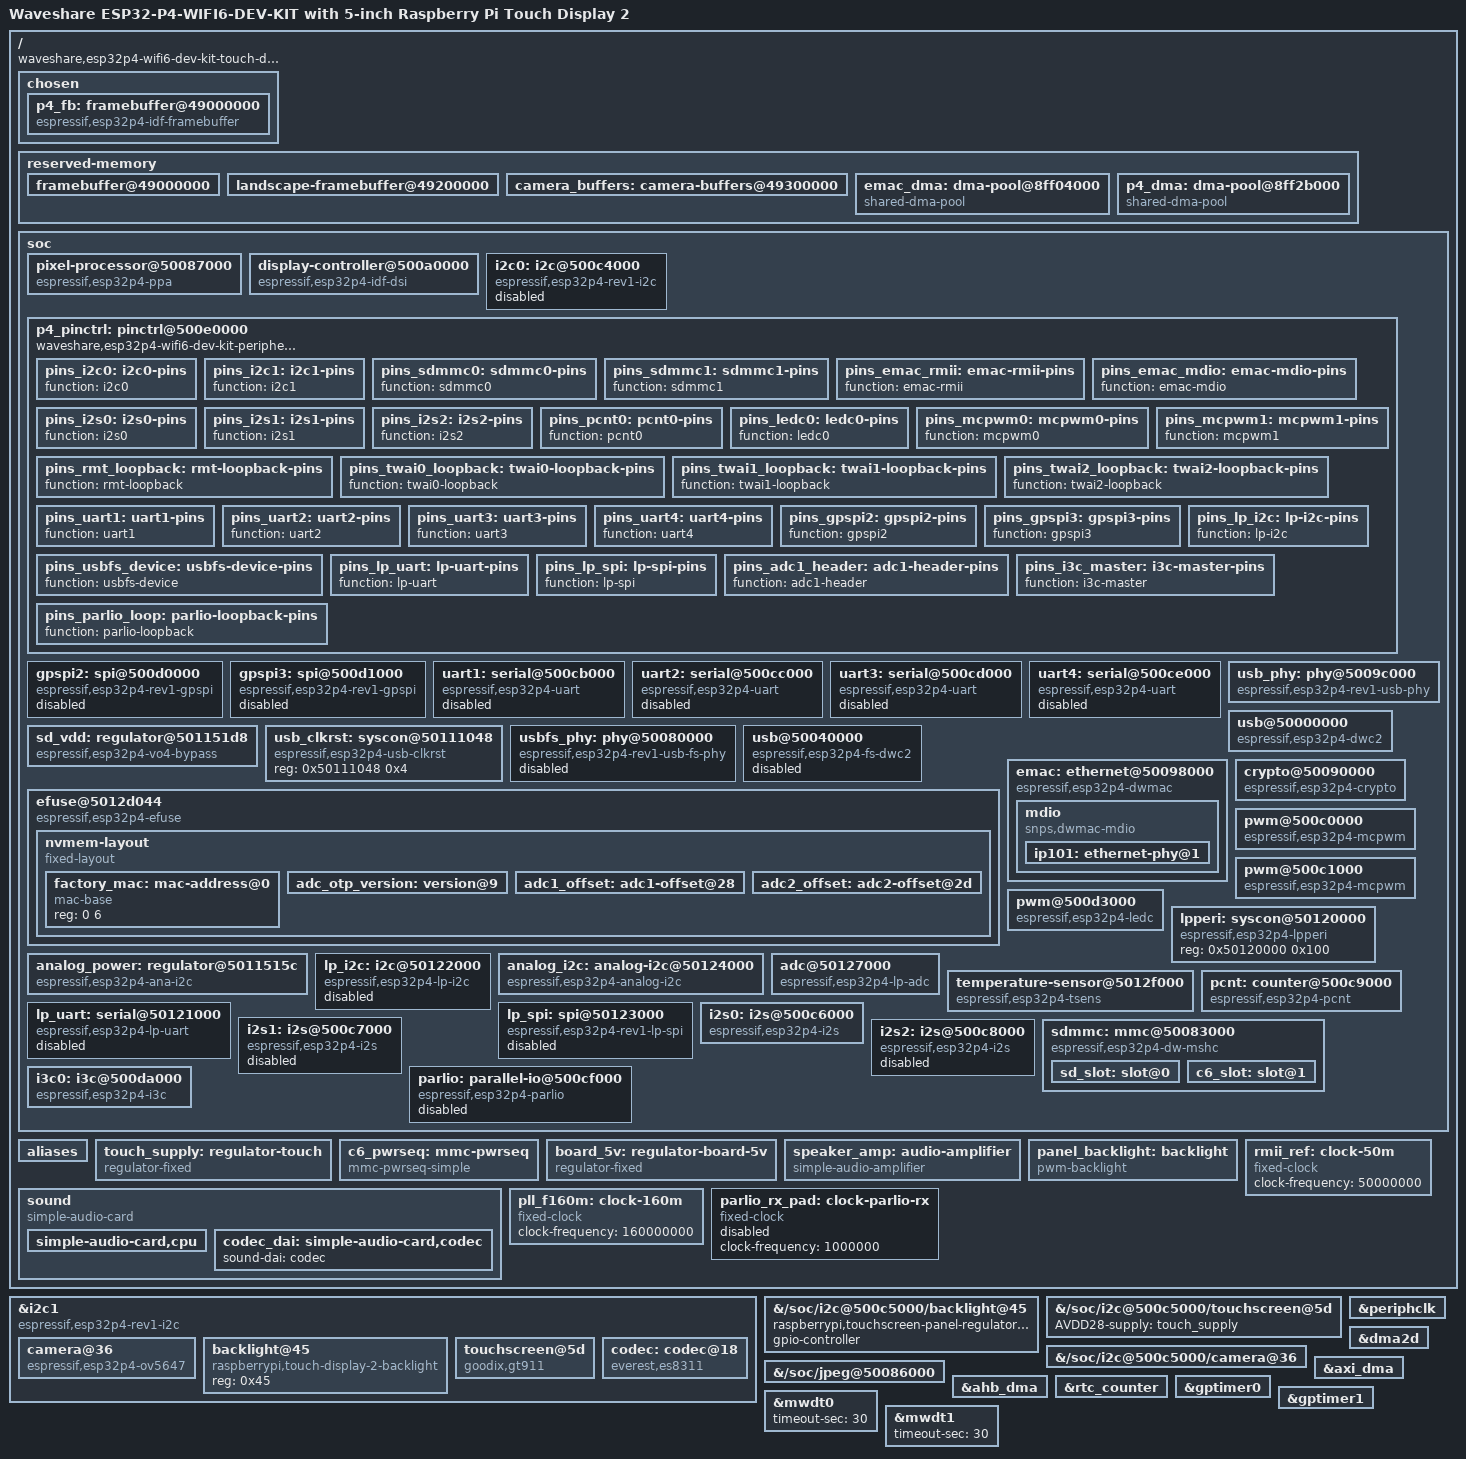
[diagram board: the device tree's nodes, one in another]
// SPDX-License-Identifier: (GPL-2.0-only OR BSD-2-Clause)
#include <dt-bindings/gpio/gpio.h>
#include <dt-bindings/clock/esp32p4-peripheral-clock.h>
#include <dt-bindings/interrupt-controller/irq.h>

/dts-v1/;
#include "esp32p4-generic.dtsi"

/ {
	chosen {
		p4_fb: framebuffer@49000000 {
			interrupts = <0x18 0x04>;
			interrupt-parent = <0x01>;
			espressif,ppa-service-entry = <0x00>;
			espressif,logical-framebuffer = <0x49200000 0xe1000 640 360 1280 720>;
			espressif,rotation-controller = <0x04>;
			espressif,scanout-controller = <0x03>;
			espressif,panel-i2c = <&i2c1>;
			espressif,panel-i2c-address = <0x45>;
			status = "okay";
			format = "r5g6b5";
			stride = <0x5a0>;
			height = <0x500>;
			width = <0x2d0>;
			reg = <0x49000000 0x1c2000>;
			compatible = "espressif,esp32p4-idf-framebuffer";
		};
	};

	reserved-memory {
		framebuffer@49000000 {
			no-map;
			reg = <0x49000000 0x1c2000>;
		};

		landscape-framebuffer@49200000 {
			no-map;
			reg = <0x49200000 0xe1000>;
		};

		camera_buffers: camera-buffers@49300000 {
			no-map;
			reg = <0x49300000 0x300000>;
		};
	};

	soc {
		pixel-processor@50087000 {
			compatible = "espressif,esp32p4-idf-ppa";
			reg = <0x50087000 0x1000 0x50088000 0x1000>;
			interrupt-parent = <0x01>;
			interrupts = <105 4 108 4>;
			phandle = <0x04>;
		};

		display-controller@500a0000 {
			compatible = "espressif,esp32p4-idf-dsi";
			reg = <0x500a0000 0x1000 0x500e603c 0x04>;
			interrupt-parent = <0x01>;
			interrupts = <86 4>;
			phandle = <0x03>;
		};
	};
};

/* Set to 1 to select UART4 DMA and reserve AHB GDMA pair 2 for it. */
#define ESP32P4_UART4_UHCI 0

&{/soc} {

	/* TRM ch.48 I2C Controller — HP I2C0 master and IRQ44. */
	i2c0: i2c@500c4000 {
		compatible = "espressif,esp32p4-rev1-i2c";
		reg = <0x500c4000 0x100>;
		interrupt-parent = <&{/soc/interrupt-controller@20800000}>;
		interrupts = <44 4>;
		clocks = <&periphclk ESP32P4_CLK_I2C0>;
		resets = <&periphclk ESP32P4_RST_I2C0>;
		pinctrl-names = "default";
		pinctrl-0 = <&pins_i2c0>;
		clock-frequency = <100000>;
		#address-cells = <1>;
		#size-cells = <0>;
		/* I2C1 owns the display pads by default. */
		status = "disabled";
	};

	p4_pinctrl: pinctrl@500e0000 {
		compatible = "waveshare,esp32p4-wifi6-dev-kit-peripheral-pinctrl";
		reg = <0x500e0000 0x700>, <0x500e1000 0x100>;
		clocks = <&periphclk ESP32P4_CLK_IOMUX>;

		pins_i2c0: i2c0-pins {
			function = "i2c0";
		};

		pins_i2c1: i2c1-pins {
			function = "i2c1";
		};

		pins_sdmmc0: sdmmc0-pins {
			function = "sdmmc0";
		};

		pins_sdmmc1: sdmmc1-pins {
			function = "sdmmc1";
		};

		pins_emac_rmii: emac-rmii-pins {
			function = "emac-rmii";
		};

		pins_emac_mdio: emac-mdio-pins {
			function = "emac-mdio";
		};

		pins_i2s0: i2s0-pins {
			function = "i2s0";
		};

		pins_i2s1: i2s1-pins {
			function = "i2s1";
		};

		pins_i2s2: i2s2-pins {
			function = "i2s2";
		};

		pins_pcnt0: pcnt0-pins {
			function = "pcnt0";
		};

		pins_ledc0: ledc0-pins {
			function = "ledc0";
		};

		pins_mcpwm0: mcpwm0-pins {
			function = "mcpwm0";
		};

		pins_mcpwm1: mcpwm1-pins {
			function = "mcpwm1";
		};

		pins_rmt_loopback: rmt-loopback-pins {
			function = "rmt-loopback";
		};

		pins_twai0_loopback: twai0-loopback-pins {
			function = "twai0-loopback";
		};

		pins_twai1_loopback: twai1-loopback-pins {
			function = "twai1-loopback";
		};

		pins_twai2_loopback: twai2-loopback-pins {
			function = "twai2-loopback";
		};

		pins_uart1: uart1-pins {
			function = "uart1";
		};

		pins_uart2: uart2-pins {
			function = "uart2";
		};

		pins_uart3: uart3-pins {
			function = "uart3";
		};

		pins_uart4: uart4-pins {
			function = "uart4";
		};

		pins_gpspi2: gpspi2-pins {
			function = "gpspi2";
		};

		pins_gpspi3: gpspi3-pins {
			function = "gpspi3";
		};
	};
};

/ {
	aliases {
		spi2 = &gpspi2;
		spi3 = &gpspi3;
	};
};

&{/soc} {
	/* TRM ch.47 SPI Controller and ch.14 Interrupt Matrix — SPI2/3. */
	/* P6 GPIO20..23. No implicit spidev or external device. */
	gpspi2: spi@500d0000 {
		compatible = "espressif,esp32p4-rev1-gpspi";
		reg = <0x500d0000 0x100>;
		clocks = <&periphclk ESP32P4_CLK_GPSPI2>;
		resets = <&periphclk ESP32P4_RST_GPSPI2>;
		interrupt-parent = <&{/soc/interrupt-controller@20800000}>;
		interrupts = <25 IRQ_TYPE_LEVEL_HIGH>;
		pinctrl-0 = <&pins_gpspi2>;
		pinctrl-names = "default";
		num-cs = <1>;
		#address-cells = <1>;
		#size-cells = <0>;
		status = "disabled";
	};

	/* P6 GPIO20..23. No implicit spidev or external device. */
	gpspi3: spi@500d1000 {
		compatible = "espressif,esp32p4-rev1-gpspi";
		reg = <0x500d1000 0x100>;
		clocks = <&periphclk ESP32P4_CLK_GPSPI3>;
		resets = <&periphclk ESP32P4_RST_GPSPI3>;
		interrupt-parent = <&{/soc/interrupt-controller@20800000}>;
		interrupts = <26 IRQ_TYPE_LEVEL_HIGH>;
		pinctrl-0 = <&pins_gpspi3>;
		pinctrl-names = "default";
		num-cs = <1>;
		#address-cells = <1>;
		#size-cells = <0>;
		status = "disabled";
	};
};

/ {
	aliases {
		serial1 = &uart1;
		serial2 = &uart2;
		serial3 = &uart3;
		serial4 = &uart4;
	};
};

&{/soc} {
	/* TRM ch.46 UART Controller and ch.14 Interrupt Matrix. */
	uart1: serial@500cb000 {
		compatible = "espressif,esp32p4-uart";
		reg = <0x500cb000 0x1000>;
		interrupt-parent = <&{/soc/interrupt-controller@20800000}>;
		interrupts = <32 IRQ_TYPE_LEVEL_HIGH>;
		clocks = <&periphclk ESP32P4_CLK_UART1>;
		resets = <&periphclk ESP32P4_RST_UART1>;
		pinctrl-names = "default";
		pinctrl-0 = <&pins_uart1>;
		status = "disabled";
	};

	uart2: serial@500cc000 {
		compatible = "espressif,esp32p4-uart";
		reg = <0x500cc000 0x1000>;
		interrupt-parent = <&{/soc/interrupt-controller@20800000}>;
		interrupts = <33 IRQ_TYPE_LEVEL_HIGH>;
		clocks = <&periphclk ESP32P4_CLK_UART2>;
		resets = <&periphclk ESP32P4_RST_UART2>;
		pinctrl-names = "default";
		pinctrl-0 = <&pins_uart2>;
		status = "disabled";
	};

	uart3: serial@500cd000 {
		compatible = "espressif,esp32p4-uart";
		reg = <0x500cd000 0x1000>;
		interrupt-parent = <&{/soc/interrupt-controller@20800000}>;
		interrupts = <34 IRQ_TYPE_LEVEL_HIGH>;
		clocks = <&periphclk ESP32P4_CLK_UART3>;
		resets = <&periphclk ESP32P4_RST_UART3>;
		pinctrl-names = "default";
		pinctrl-0 = <&pins_uart3>;
		status = "disabled";
	};

	uart4: serial@500ce000 {
		compatible = "espressif,esp32p4-uart";
		reg = <0x500ce000 0x1000>;
		interrupt-parent = <&{/soc/interrupt-controller@20800000}>;
		interrupts = <35 IRQ_TYPE_LEVEL_HIGH>;
		clocks = <&periphclk ESP32P4_CLK_UART4>;
		resets = <&periphclk ESP32P4_RST_UART4>;
		pinctrl-names = "default";
		pinctrl-0 = <&pins_uart4>;
		status = "disabled";
	};
};

/ {
	model = "Waveshare ESP32-P4-WIFI6-DEV-KIT with 5-inch Raspberry Pi Touch Display 2";
	compatible = "waveshare,esp32p4-wifi6-dev-kit-touch-display-2",
		     "waveshare,esp32p4-wifi6-dev-kit",
		     "espressif,esp32p4-generic", "espressif,esp32p4";

	aliases {
		i2c1 = &i2c1;
		spi4 = &lp_spi;
		serial5 = &lp_uart;
		mmc0 = &sd_slot;
		mmc1 = &c6_slot;
		ethernet0 = &emac;
		watchdog0 = &mwdt0;
		watchdog1 = &mwdt1;
	};

	/* The panel MCU exposes LCD reset on GPIO0 and CTP reset on GPIO1. */
	touch_supply: regulator-touch {
		compatible = "regulator-fixed";
		regulator-name = "touch-display-2";
		gpio = <&panel_mcu 1 GPIO_ACTIVE_HIGH>;
		enable-active-high;
		startup-delay-us = <50000>;
	};

	c6_pwrseq: mmc-pwrseq {
		compatible = "mmc-pwrseq-simple";
		reset-gpios = <&p4_pinctrl 54 GPIO_ACTIVE_LOW>;
		/* ESP-Hosted firmware starts after the SDIO bus is pulled up. */
		post-power-on-delay-ms = <200>;
		power-off-delay-us = <10000>;
	};

	board_5v: regulator-board-5v {
		compatible = "regulator-fixed";
		regulator-name = "VCC_5V";
		regulator-min-microvolt = <5000000>;
		regulator-max-microvolt = <5000000>;
		regulator-always-on;
	};

	speaker_amp: audio-amplifier {
		compatible = "simple-audio-amplifier";
		enable-gpios = <&p4_pinctrl 53 GPIO_ACTIVE_HIGH>;
		VCC-supply = <&board_5v>;
		sound-name-prefix = "PA";
	};

	sound {
		compatible = "simple-audio-card";
		simple-audio-card,name = "Waveshare ES8311";
		simple-audio-card,format = "i2s";
		simple-audio-card,bitclock-master = <&codec_dai>;
		simple-audio-card,frame-master = <&codec_dai>;
		simple-audio-card,mclk-fs = <256>;
		simple-audio-card,aux-devs = <&speaker_amp>;
		simple-audio-card,widgets = "Speaker", "Speaker", "Microphone", "Mic";
		simple-audio-card,routing = "Speaker", "PA OUTL", "PA INL", "OUT",
					   "MIC1", "Mic";

		simple-audio-card,cpu {
			sound-dai = <&i2s0>;
			system-clock-direction-out;
		};

		codec_dai: simple-audio-card,codec {
			sound-dai = <&codec>;
		};
	};

	panel_backlight: backlight {
		compatible = "pwm-backlight";
		pwms = <&panel_mcu 0 200000 0>;
		brightness-levels = <0 31>;
		num-interpolated-steps = <31>;
		default-brightness-level = <16>;
	};
};

/* TRM ch.48 I2C Controller - I2C1 APB gate, XTAL source and master mode.
 * The panel MCU and touchscreen are on GPIO7 (SDA) and GPIO8 (SCL).
 */
&i2c1 {
	/delete-property/ status;
	compatible = "espressif,esp32p4-rev1-i2c";
	reg = <0x500c5000 0x100>;
	clocks = <&periphclk ESP32P4_CLK_I2C1>;
	resets = <&periphclk ESP32P4_RST_I2C1>;
	pinctrl-0 = <&pins_i2c1>;
	pinctrl-names = "default";
	clock-frequency = <100000>;

	camera@36 {
		compatible = "espressif,esp32p4-ov5647";
		reg = <0x36>;
		interrupt-parent = <0x01>;
		interrupts = <24 4>;
	};

	backlight@45 {
		compatible = "raspberrypi,touch-display-2-backlight";
		reg = <0x45>;
	};

	touchscreen@5d {
		compatible = "goodix,gt911";
		reg = <0x5d>;
		touchscreen-size-x = <720>;
		touchscreen-size-y = <1280>;
		touchscreen-inverted-x;
		touchscreen-swapped-x-y;
		touchscreen-x-mm = <62>;
		touchscreen-y-mm = <110>;
	};

	codec: codec@18 {
		compatible = "everest,es8311";
		reg = <0x18>;
		clocks = <&periphclk ESP32P4_CLK_I2S0>;
		clock-names = "mclk";
		#sound-dai-cells = <0>;
	};
};

&{/chosen/framebuffer@49000000} {
	reset-gpios = <&panel_mcu 0 GPIO_ACTIVE_LOW>;
	backlight = <&panel_backlight>;
};

panel_mcu: &{/soc/i2c@500c5000/backlight@45} {
	compatible = "raspberrypi,touchscreen-panel-regulator-v2";
	gpio-controller;
	#gpio-cells = <2>;
	#pwm-cells = <3>;
};

&{/soc/i2c@500c5000/touchscreen@5d} {
	AVDD28-supply = <&touch_supply>;
};

/* TRM ch.9 System and Memory - CPU and DMA aliases of HP L2MEM. */
&{/reserved-memory} {
	emac_dma: dma-pool@8ff04000 {
		compatible = "shared-dma-pool";
		reg = <0x8ff04000 0x10000>;
		no-map;
	};

	p4_dma: dma-pool@8ff2b000 {
		compatible = "shared-dma-pool";
		reg = <0x8ff2b000 0x11000>;
		no-map;
		linux,dma-default;
	};
};

&{/soc} {
	dma-noncoherent;
	dma-ranges = <0x48000000 0x48000000 0x04000000>,
		     <0x4ff04000 0x8ff04000 0x10000>,
		     <0x4ff2b000 0x8ff2b000 0x11000>;
};

/ {
	rmii_ref: clock-50m {
		compatible = "fixed-clock";
		#clock-cells = <0>;
		clock-frequency = <50000000>;
	};

	pll_f160m: clock-160m {
		compatible = "fixed-clock";
		#clock-cells = <0>;
		clock-frequency = <160000000>;
	};
};

&p4_pinctrl {
	reg = <0x500e0000 0x700>, <0x500e1000 0x100>,
	      <0x5012a000 0x200>, <0x5012b000 0x100>;
	gpio-controller;
	#gpio-cells = <2>;
	gpio-ranges = <&p4_pinctrl 0 0 57>;
	gpio-reserved-ranges = <0 51>, <52 1>, <55 2>;

	pins_lp_i2c: lp-i2c-pins {
		function = "lp-i2c";
	};

	pins_usbfs_device: usbfs-device-pins {
		function = "usbfs-device";
	};

	pins_lp_uart: lp-uart-pins {
		function = "lp-uart";
	};

	pins_lp_spi: lp-spi-pins {
		function = "lp-spi";
	};

	pins_adc1_header: adc1-header-pins {
		function = "adc1-header";
	};
};

/*
 * TRM v1.3 ch.7.3.3.1: these ranges are in the PSRAM window.
 * Native DSI uses the portrait framebuffer directly.
 */
/delete-node/ &{/reserved-memory/landscape-framebuffer@49200000};

&{/chosen/framebuffer@49000000} {
	/delete-property/ espressif,logical-framebuffer;
};

&{/soc/i2c@500c5000/camera@36} {
	memory-region = <&camera_buffers>;
	espressif,mipi-supplier = <&p4_fb>;
	status = "okay";
};

&periphclk {
	/delete-property/ status;
	espressif,lpperi = <&lpperi>;
	reg = <0x500e6000 0x100>, <0x5011104c 0x4>,
	      <0x50111040 0x4>, <0x500e514c 0x4>, <0x50111000 0x4>;
	clocks = <&xtal>, <&pll_f160m>, <&rmii_ref>, <&parlio_rx_pad>;
};

&{/soc} {
	/* TRM ch.16 Low-Power Management - VO4 bypass supplies SD1_VDD. */
	sd_vdd: regulator@501151d8 {
		compatible = "espressif,esp32p4-vo4-bypass";
		reg = <0x501151d8 0x4>;
		regulator-name = "SD1_VDD";
		regulator-min-microvolt = <3300000>;
		regulator-max-microvolt = <3300000>;
	};

	/* TRM ch.54 USB 2.0 High-Speed OTG - UTMI PHY and host controller. */
	usb_phy: phy@5009c000 {
		compatible = "espressif,esp32p4-rev1-usb-phy";
		reg = <0x5009c000 0x20>, <0x500e515c 0x4>;
		reg-names = "utmi", "phy-ctrl";
		espressif,otg-clkrst = <&usb_clkrst>;
		clocks = <&periphclk ESP32P4_CLK_USBHS>;
		#phy-cells = <0>;
	};

	usb@50000000 {
		compatible = "espressif,esp32p4-dwc2";
		reg = <0x50000000 0x1000>;
		interrupt-parent = <&{/soc/interrupt-controller@20800000}>;
		interrupts = <93 4>;
		phys = <&usb_phy>;
		phy-names = "usb2-phy";
		dr_mode = "host";
	};

	/* TRM ch.12 — FS/HS resets share LP_CLKRST_HP_USB_CLKRST_CTRL1. */
	usb_clkrst: syscon@50111048 {
		compatible = "espressif,esp32p4-usb-clkrst", "syscon";
		reg = <0x50111048 0x4>;
	};

	/* TRM ch.55 USB Full-Speed OTG — internal PHY 0 on the debug connector. */
	usbfs_phy: phy@50080000 {
		compatible = "espressif,esp32p4-rev1-usb-fs-phy";
		reg = <0x50080000 0x4>, <0x50111044 0x4>, <0x50110100 0x4>;
		reg-names = "wrap", "phy-clock", "phy-route";
		clocks = <&periphclk ESP32P4_CLK_USBFS>;
		espressif,otg-clkrst = <&usb_clkrst>;
		espressif,phy-index = <0>;
		espressif,shared-serial-jtag = <&usb_serial_jtag>;
		#phy-cells = <0>;
		status = "disabled";
	};

	usb@50040000 {
		compatible = "espressif,esp32p4-fs-dwc2";
		reg = <0x50040000 0x1000>;
		interrupt-parent = <&{/soc/interrupt-controller@20800000}>;
		interrupts = <103 4>;
		phys = <&usbfs_phy>;
		phy-names = "usb2-phy";
		maximum-speed = "full-speed";
		dr_mode = "peripheral";
		pinctrl-names = "default";
		pinctrl-0 = <&pins_usbfs_device>;
		/* TRM ch.55 GHWCFG3.DFIFO_DEPTH reports 200 words on rev1.3. */
		g-rx-fifo-size = <64>;
		g-np-tx-fifo-size = <16>;
		g-tx-fifo-size = <32 32 16 16>;
		status = "disabled";
	};

	/* TRM ch.10 eFuse Controller - RD_MAC_SYS0 through RD_MAC_SYS1. */
	efuse@5012d044 {
		compatible = "espressif,esp32p4-efuse";
		reg = <0x5012d044 0x30>;
		read-only;

		nvmem-layout {
			compatible = "fixed-layout";
			#address-cells = <1>;
			#size-cells = <1>;

			factory_mac: mac-address@0 {
				compatible = "mac-base";
				#nvmem-cell-cells = <1>;
				reg = <0 6>;
			};

			/* TRM ch.10 eFuse Controller — BLOCK1/2 read shadows. */
			adc_otp_version: version@9 {
				reg = <0x09 1>;
				bits = <0 5>;
			};

			adc1_offset: adc1-offset@28 {
				reg = <0x28 2>;
				bits = <0 10>;
			};

			adc2_offset: adc2-offset@2d {
				reg = <0x2d 2>;
				bits = <0 10>;
			};
		};
	};

	/* TRM ch.57 EMAC - 10/100 RMII PHY with external 50 MHz clock. */
	emac: ethernet@50098000 {
		compatible = "espressif,esp32p4-dwmac";
		reg = <0x50098000 0x2000>;
		memory-region = <&emac_dma>;
		interrupt-parent = <&{/soc/interrupt-controller@20800000}>;
		interrupts = <92 4>, <91 4>, <90 4>;
		interrupt-names = "macirq", "eth_wake_irq", "eth_lpi";
		clocks = <&periphclk ESP32P4_CLK_EMAC>,
			 <&periphclk ESP32P4_CLK_EMAC_RMII>,
			 <&periphclk ESP32P4_CLK_EMAC_PTP>;
		clock-names = "stmmaceth", "rmii", "ptp_ref";
		pinctrl-0 = <&pins_emac_rmii &pins_emac_mdio>;
		pinctrl-names = "default";
		phy-mode = "rmii";
		phy-handle = <&ip101>;
		/* P4 has no native Wi-Fi or Bluetooth MAC address allocation. */
		nvmem-cells = <&factory_mac 0>;
		nvmem-cell-names = "mac-address";
		max-speed = <100>;
		snps,clk-csr = <4>;
		/* TRM ch.57 EMAC - the AHB master aligns subsequent bursts. */
		snps,aal;
		snps,pbl = <32>;
		snps,no-pbl-x8;

		mdio {
			compatible = "snps,dwmac-mdio";
			#address-cells = <1>;
			#size-cells = <0>;

			ip101: ethernet-phy@1 {
				reg = <1>;
				reset-gpios = <&p4_pinctrl 51 GPIO_ACTIVE_LOW>;
				reset-assert-us = <10000>;
				reset-deassert-us = <30000>;
			};
		};
	};

	/*
	 * TRM ch.28/32 AES/SHA, ch.31 RSA, and ch.29 ECC. On rev1.3,
	 * ECC_MULT_DATE at 0x500930fc reads 0x02305040, matching the
	 * hw_ver1 ECC block. The summary map lists the crypto banks in
	 * a different order.
	 */
	crypto@50090000 {
		compatible = "espressif,esp32p4-crypto";
		reg = <0x50090000 0x2000>, <0x50092000 0x1000>,
		      <0x50093000 0x1000>, <0x500e51d4 0x4>;
		reg-names = "aes-sha", "rsa", "ecc", "ecc-power";
		clocks = <&periphclk ESP32P4_CLK_AES_SHA>,
			 <&periphclk ESP32P4_CLK_RSA>,
			 <&periphclk ESP32P4_CLK_ECC>;
		clock-names = "aes-sha", "rsa", "ecc";
	};

	/* TRM ch.61 Motor Control PWM - three timer/operator pairs per group. */
	pwm@500c0000 {
		compatible = "espressif,esp32p4-mcpwm";
		reg = <0x500c0000 0x1000>;
		clocks = <&periphclk ESP32P4_CLK_MCPWM0>;
		resets = <&periphclk ESP32P4_RST_MCPWM0>;
		#pwm-cells = <3>;
	};

	pwm@500c1000 {
		compatible = "espressif,esp32p4-mcpwm";
		reg = <0x500c1000 0x1000>;
		clocks = <&periphclk ESP32P4_CLK_MCPWM1>;
		resets = <&periphclk ESP32P4_RST_MCPWM1>;
		#pwm-cells = <3>;
	};

	/* TRM ch.60 LED PWM Controller - one low-speed group, eight outputs. */
	pwm@500d3000 {
		compatible = "espressif,esp32p4-ledc";
		reg = <0x500d3000 0x1000>;
		clocks = <&periphclk ESP32P4_CLK_LEDC>;
		resets = <&periphclk ESP32P4_RST_LEDC>;
		#pwm-cells = <3>;
	};

	/* TRM ch.12 Reset and Clock — LPPERI_CLK_EN, RESET_EN and ADC_CTRL. */
	lpperi: syscon@50120000 {
		compatible = "espressif,esp32p4-lpperi", "syscon";
		reg = <0x50120000 0x100>;
	};

	/* TRM ch.16 Low-Power Management — PMU_RF_PWC. */
	analog_power: regulator@5011515c {
		compatible = "espressif,esp32p4-ana-i2c";
		reg = <0x5011515c 0x4>;
		regulator-name = "p4-sar-analog";
	};

	/* TRM ch.48 I2C Controller — LP I2C master, IRQ11, 16-byte FIFO. */
	lp_i2c: i2c@50122000 {
		compatible = "espressif,esp32p4-lp-i2c";
		reg = <0x50122000 0x100>;
		interrupt-parent = <&{/soc/interrupt-controller@20800000}>;
		interrupts = <11 4>;
		clocks = <&periphclk ESP32P4_CLK_LP_I2C>;
		resets = <&periphclk ESP32P4_RST_LP_I2C>;
		pinctrl-names = "default";
		pinctrl-0 = <&pins_lp_i2c>;
		clock-frequency = <100000>;
		#address-cells = <1>;
		#size-cells = <0>;
		/* I2C1 owns the display pads by default. */
		status = "disabled";
	};

	/* TRM ch.49 Analog I2C Controller — I2C0_CTRL, ANA_CONF2. */
	analog_i2c: analog-i2c@50124000 {
		compatible = "espressif,esp32p4-analog-i2c";
		reg = <0x50124000 0x3c>;
		espressif,lpperi = <&lpperi>;
		analog-supply = <&analog_power>;
	};

	/* TRM ch.67 ADC Controller — shared SAR1, LP one-shot and HP DMA. */
	adc@50127000 {
		compatible = "espressif,esp32p4-lp-adc";
		reg = <0x50127000 0x100>, <0x500de000 0x100>;
		reg-names = "lp", "hp";
		clocks = <&periphclk ESP32P4_CLK_ADC>;
		resets = <&periphclk ESP32P4_RST_ADC>;
		dmas = <&ahb_dma 2 8>;
		dma-names = "rx";
		espressif,lpperi = <&lpperi>;
		espressif,adc-inputs = <4 5 6 7>;
		espressif,analog-i2c = <&analog_i2c>;
		nvmem-cells = <&adc_otp_version>, <&adc1_offset>, <&adc2_offset>;
		nvmem-cell-names = "otp-version", "adc1-offset", "adc2-offset";
		analog-supply = <&analog_power>;
		pinctrl-names = "default";
		pinctrl-0 = <&pins_adc1_header>;
	};

	/* TRM ch.66 Temperature Sensor - TSENS_OUT and LP_TSENS_INTR. */
	temperature-sensor@5012f000 {
		compatible = "espressif,esp32p4-tsens";
		reg = <0x5012f000 0x2c>;
		reg-names = "tsens";
		espressif,analog-i2c = <&analog_i2c>;
		espressif,lpperi = <&lpperi>;
		analog-supply = <&analog_power>;
		interrupt-parent = <&{/soc/interrupt-controller@20800000}>;
		interrupts = <15 4>;
	};

	/* TRM ch.53 PCNT - four units, GPIO2 feeds unit 0 channel 0. */
	pcnt: counter@500c9000 {
		compatible = "espressif,esp32p4-pcnt";
		reg = <0x500c9000 0x100>;
		interrupt-parent = <&{/soc/interrupt-controller@20800000}>;
		interrupts = <111 4>;
		clocks = <&periphclk ESP32P4_CLK_PCNT>;
		resets = <&periphclk ESP32P4_RST_PCNT>;
		pinctrl-0 = <&pins_pcnt0>;
		pinctrl-names = "default";
	};

	/* TRM ch.46 UART Controller — LP UART at 0x50121000. */
	lp_uart: serial@50121000 {
		compatible = "espressif,esp32p4-lp-uart";
		reg = <0x50121000 0x100>;
		interrupt-parent = <&{/soc/interrupt-controller@20800000}>;
		interrupts = <16 4>;
		clocks = <&periphclk ESP32P4_CLK_LP_UART>;
		resets = <&periphclk ESP32P4_RST_LP_UART>;
		pinctrl-names = "default";
		pinctrl-0 = <&pins_lp_uart>;
		status = "disabled";
	};

	/* TRM ch.47 SPI Controller — LP SPI with a single native CS. */
	lp_spi: spi@50123000 {
		compatible = "espressif,esp32p4-rev1-lp-spi";
		reg = <0x50123000 0x100>;
		interrupt-parent = <&{/soc/interrupt-controller@20800000}>;
		interrupts = <13 4>;
		clocks = <&periphclk ESP32P4_CLK_LP_SPI>;
		resets = <&periphclk ESP32P4_RST_LP_SPI>;
		pinctrl-names = "default";
		pinctrl-0 = <&pins_lp_spi>;
		num-cs = <1>;
		#address-cells = <1>;
		#size-cells = <0>;
		status = "disabled";
	};

	/* TRM ch.51 I2S Controller and ch.6 GDMA - I2S0 request 3. */
	i2s0: i2s@500c6000 {
		compatible = "espressif,esp32p4-i2s";
		reg = <0x500c6000 0x1000>;
		clocks = <&periphclk ESP32P4_CLK_I2S0>;
		resets = <&periphclk ESP32P4_RST_I2S0>;
		dmas = <&ahb_dma 1 3>, <&ahb_dma 0 3>;
		dma-names = "tx", "rx";
		pinctrl-0 = <&pins_i2s0>;
		pinctrl-names = "default";
		#sound-dai-cells = <0>;
		espressif,external-card;
	};

	/* TRM ch.51 I2S and ch.6 GDMA — I2S1 trigger 4. */
	i2s1: i2s@500c7000 {
		compatible = "espressif,esp32p4-i2s";
		reg = <0x500c7000 0x1000>;
		clocks = <&periphclk ESP32P4_CLK_I2S1>;
		resets = <&periphclk ESP32P4_RST_I2S1>;
		dmas = <&ahb_dma 1 4>, <&ahb_dma 0 4>;
		dma-names = "tx", "rx";
		pinctrl-0 = <&pins_i2s1>;
		pinctrl-names = "default";
		#sound-dai-cells = <0>;
		espressif,external-card;
		status = "disabled";
	};

	/* TRM ch.51 I2S and ch.6 GDMA — I2S2 trigger 5. */
	i2s2: i2s@500c8000 {
		compatible = "espressif,esp32p4-i2s";
		reg = <0x500c8000 0x1000>;
		clocks = <&periphclk ESP32P4_CLK_I2S2>;
		resets = <&periphclk ESP32P4_RST_I2S2>;
		dmas = <&ahb_dma 1 5>, <&ahb_dma 0 5>;
		dma-names = "tx", "rx";
		pinctrl-0 = <&pins_i2s2>;
		pinctrl-names = "default";
		#sound-dai-cells = <0>;
		espressif,external-card;
		status = "disabled";
	};

	/* TRM ch.59 SD/MMC Host Controller - dedicated IOMUX slot 0. */
	sdmmc: mmc@50083000 {
		compatible = "espressif,esp32p4-dw-mshc";
		reg = <0x50083000 0x1000>;
		interrupt-parent = <&{/soc/interrupt-controller@20800000}>;
		interrupts = <23 4>;
		clocks = <&periphclk ESP32P4_CLK_SDMMC>,
			 <&periphclk ESP32P4_CLK_SDMMC>;
		clock-names = "biu", "ciu";
		assigned-clocks = <&periphclk ESP32P4_CLK_SDMMC>;
		assigned-clock-rates = <40000000>;
		pinctrl-0 = <&pins_sdmmc0 &pins_sdmmc1>;
		pinctrl-names = "default";
		espressif,num-slots = <2>;
		#address-cells = <1>;
		#size-cells = <0>;

		sd_slot: slot@0 {
			reg = <0>;
			vmmc-supply = <&sd_vdd>;
			bus-width = <4>;
			cap-sd-highspeed;
			max-frequency = <40000000>;
			no-1-8-v;
			disable-wp;
			broken-cd;
			no-mmc;
			no-sdio;
		};

		c6_slot: slot@1 {
			reg = <1>;
			mmc-pwrseq = <&c6_pwrseq>;
			bus-width = <4>;
			max-frequency = <20000000>;
			no-1-8-v;
			non-removable;
			cap-sdio-irq;
			no-mmc;
			no-sd;
		};
	};
};

&{/soc/pixel-processor@50087000} {
	compatible = "espressif,esp32p4-ppa";
	reg = <0x50087000 0x1000>;
	interrupts = <96 4>;
	clocks = <&periphclk ESP32P4_CLK_PPA>;
	resets = <&periphclk ESP32P4_RST_PPA>;
	dmas = <&dma2d 0>;
	dma-names = "srm";
};

/* I3C and PARLIO share GPIO4/5. PARLIO also shares GPIO20/21 with ADC and SPI. */
&p4_pinctrl {
	pins_i3c_master: i3c-master-pins {
		function = "i3c-master";
	};
};

&{/soc} {
	/* TRM ch.50 I3C master, ch.14 I3C_MST_INTR source 101. */
	i3c0: i3c@500da000 {
		compatible = "espressif,esp32p4-i3c";
		reg = <0x500da000 0x200>;
		interrupt-parent = <&{/soc/interrupt-controller@20800000}>;
		interrupts = <101 4>;
		clocks = <&periphclk ESP32P4_CLK_I3C>;
		resets = <&periphclk ESP32P4_RST_I3C>;
		pinctrl-names = "default";
		pinctrl-0 = <&pins_i3c_master>;
		i3c-scl-hz = <10000000>;
		#address-cells = <3>;
		#size-cells = <0>;
		status = "okay";
	};
};

/ {
	/* The loopback routes the configured TX clock to the receiver pad. */
	parlio_rx_pad: clock-parlio-rx {
		compatible = "fixed-clock";
		#clock-cells = <0>;
		clock-frequency = <1000000>;
		status = "disabled";
	};
};

&p4_pinctrl {
	pins_parlio_loop: parlio-loopback-pins {
		function = "parlio-loopback";
	};
};

&{/soc} {
	/* P4 v1.3 TRM ch.63 PARLIO, ch.6 AXI GDMA peripheral selector 3. */
	parlio: parallel-io@500cf000 {
		compatible = "espressif,esp32p4-parlio";
		reg = <0x500cf000 0x400>;
		interrupt-parent = <&{/soc/interrupt-controller@20800000}>;
		interrupts = <113 4>, <114 4>;
		interrupt-names = "rx", "tx";
		clocks = <&periphclk ESP32P4_CLK_PARLIO_BUS>,
			 <&periphclk ESP32P4_CLK_PARLIO_RX>,
			 <&periphclk ESP32P4_CLK_PARLIO_TX>,
			 <&xtal>, <&parlio_rx_pad>;
		clock-names = "bus", "rx", "tx", "xtal", "rx-pad";
		resets = <&periphclk ESP32P4_RST_PARLIO_BUS>,
			 <&periphclk ESP32P4_RST_PARLIO_RX>,
			 <&periphclk ESP32P4_RST_PARLIO_TX>;
		reset-names = "bus", "rx", "tx";
		dmas = <&axi_dma 2 3>, <&axi_dma 1 3>;
		dma-names = "rx", "tx";
		pinctrl-names = "default";
		pinctrl-0 = <&pins_parlio_loop>;
		espressif,data-width = <4>;
		clock-frequency = <1000000>;
		status = "disabled";
	};
};

#if ESP32P4_UART4_UHCI
/* TRM ch.46 UHCI_CONF0.UART_SEL and ch.6 AHB GDMA peripheral request 2. */
&uart4 {
	compatible = "espressif,esp32p4-uhci-uart";
	reg = <0x500ce000 0x1000>, <0x500df000 0x100>;
	reg-names = "uart", "uhci";
	/delete-property/ interrupt-parent;
	/delete-property/ interrupts;
	clocks = <&periphclk ESP32P4_CLK_UART4>, <&periphclk ESP32P4_CLK_UHCI>;
	clock-names = "uart", "bus";
	resets = <&periphclk ESP32P4_RST_UART4>, <&periphclk ESP32P4_RST_UHCI>;
	reset-names = "uart", "uhci";
	dmas = <&ahb_dma 2 2>;
	dma-names = "tx";
	status = "okay";
};

/* Pair 2 is dedicated to UHCI. Keep the ADC's LP one-shot controller. */
&{/soc/adc@50127000} {
	reg = <0x50127000 0x100>;
	/delete-property/ reg-names;
	/delete-property/ clocks;
	/delete-property/ resets;
	/delete-property/ dmas;
	/delete-property/ dma-names;
};
#endif

&{/soc/jpeg@50086000} {
	/delete-property/ status;
};

&dma2d {
	/delete-property/ status;
};

&axi_dma {
	/delete-property/ status;
};

&ahb_dma {
	/delete-property/ status;
};

&rtc_counter {
	/delete-property/ status;
};

&gptimer0 {
	/delete-property/ status;
};

&gptimer1 {
	/delete-property/ status;
};

&mwdt0 {
	/delete-property/ status;
	timeout-sec = <30>;
};

&mwdt1 {
	/delete-property/ status;
	timeout-sec = <30>;
};
